AUTOSAR XML (schema 00046)
package /HuaweiMDC/PlatformServices/CanbusAbstractApplication
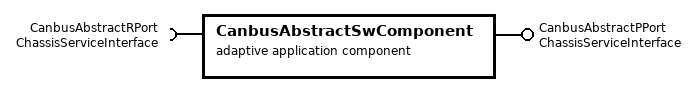
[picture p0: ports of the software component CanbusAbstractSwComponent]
  adaptive application sw component type CanbusAbstractSwComponent
    provide port CanbusAbstractPPort: provided-interface=ChassisServiceInterface
    require port CanbusAbstractRPort: required-interface=ChassisServiceInterface
package /HuaweiMDC/PlatformServices/CanbusAbstractExecutable
  executable CanbusAbstractExecutable
    root sw component prototype CanbusAbstractRootSwComponent: application-type=CanbusAbstractSwComponent
